VERSION ""

NS_ :

BS_:

BU_: Receiver ChassisBus VehicleBus

BO_ 962 ID3C2VCLswitches: 8 VehicleBus

BO_ 822 ID336MaxPowerRating: 3 VehicleBus
 SG_ Drive_Regen_Rating336 : 16|8@1+ (1,-100) [-100|155] "kW" Vector__XXX
 SG_ Drive_Power_Rating336 : 0|9@1+ (1,0) [0|511] "kW" Vector__XXX

BO_ 819 ID333UIcharging: 4 VehicleBus
 SG_ Charge_To_SOC333 : 16|10@1+ (0.1,0) [0|102.3] "%" Vector__XXX
 SG_ Charge_Current_Limit333 : 8|7@1+ (1,0) [0|127] "A" Vector__XXX

BO_ 577 ID241Coolant: 7 VehicleBus
 SG_ VCFPT_Coolant_Flow241 : 22|9@1+ (0.1,0) [0|51.1] "LPM" Vector__XXX
 SG_ VCF_batt_Coolant_Flow241 : 0|9@1+ (0.1,0) [0|51.1] "LPM" Vector__XXX

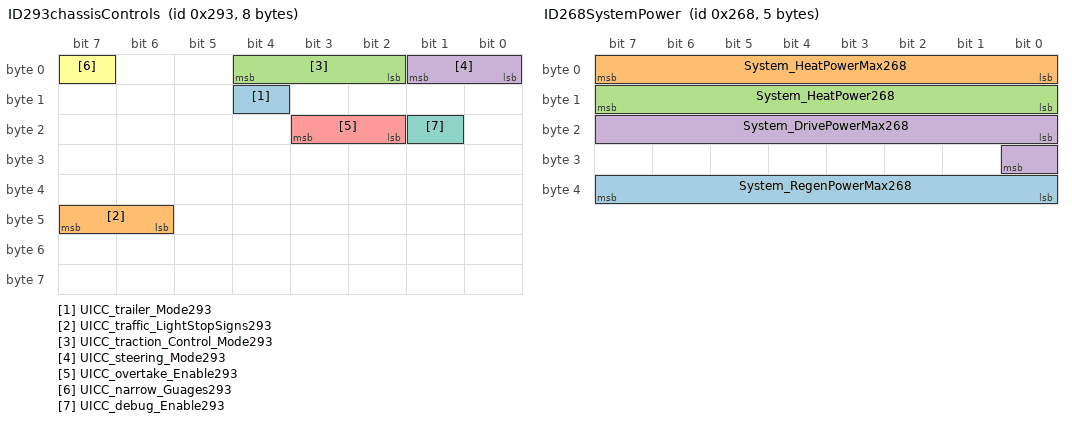
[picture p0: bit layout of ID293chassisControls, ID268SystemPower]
BO_ 659 ID293chassisControls: 8 VehicleBus
 SG_ UICC_trailer_Mode293 : 12|1@1+ (1,0) [0|1] "" Vector__XXX
 SG_ UICC_traffic_LightStopSigns293 : 46|2@1+ (1,0) [0|0] "" Vector__XXX
 SG_ UICC_traction_Control_Mode293 : 2|3@1+ (1,0) [0|7] "" Vector__XXX
 SG_ UICC_steering_Mode293 : 0|2@1+ (1,0) [0|3] "" Vector__XXX
 SG_ UICC_overtake_Enable293 : 18|2@1+ (1,0) [0|0] "" Vector__XXX
 SG_ UICC_narrow_Guages293 : 7|1@1+ (1,0) [0|1] "" Vector__XXX
 SG_ UICC_debug_Enable293 : 17|1@1+ (1,0) [0|1] "" Vector__XXX

BO_ 616 ID268SystemPower: 5 VehicleBus
 SG_ System_RegenPowerMax268 : 32|8@1+ (1,-100) [-100|155] "kW" Vector__XXX
 SG_ System_HeatPowerMax268 : 0|8@1+ (0.08,0) [0|31875] "kW" Vector__XXX
 SG_ System_HeatPower268 : 8|8@1+ (0.08,0) [0|31875] "kW" Vector__XXX
 SG_ System_DrivePowerMax268 : 16|9@1+ (1,0) [0|511] "kW" Vector__XXX

BO_ 79 ID04FGPSLatLong: 8 ChassisBus
 SG_ GPS_Longitude04F : 28|28@1- (1E-006,0) [-1342.17728|1342.17727] "Deg"  Receiver
 SG_ GPS_Lattitude04F : 0|28@1- (1E-006,0) [-134.217728|134.217727] "Deg"  Receiver

BO_ 978 ID3D2TotalChargeDischarge: 8 VehicleBus
 SG_ Total_Discharge3D2 : 0|32@1+ (0.001,0) [0|4294967.295] "kWh" Vector__XXX
 SG_ Total_Charge3D2 : 32|32@1+ (0.001,0) [0|4294967.295] "kWh" Vector__XXX

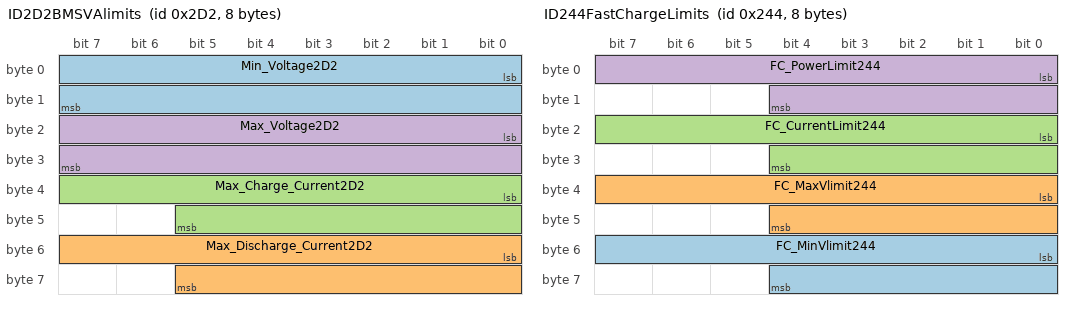
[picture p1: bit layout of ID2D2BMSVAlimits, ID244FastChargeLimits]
BO_ 722 ID2D2BMSVAlimits: 8 VehicleBus
 SG_ Min_Voltage2D2 : 0|16@1+ (0.01,0) [0|655.35] "V" Vector__XXX
 SG_ Max_Discharge_Current2D2 : 48|14@1+ (0.128,0) [0|2097.024] "A" Vector__XXX
 SG_ Max_Charge_Current2D2 : 32|14@1+ (0.1,0) [0|1638.3] "A" Vector__XXX
 SG_ Max_Voltage2D2 : 16|16@1+ (0.01,0) [0|655.35] "V" Vector__XXX

BO_ 1345 ID541FastChargeMaxLimits: 8 VehicleBus
 SG_ FCMax_Power_Limit541 : 0|13@1+ (0.062256,0) [0|509.938896] "kW" Vector__XXX
 SG_ FCMax_Current_Limit541 : 16|13@1+ (0.073242,0) [0|599.925222] "A" Vector__XXX

BO_ 580 ID244FastChargeLimits: 8 VehicleBus
 SG_ FC_MinVlimit244 : 48|13@1+ (0.073242,0) [0|599.925222] "V" Vector__XXX
 SG_ FC_MaxVlimit244 : 32|13@1+ (0.073242,0) [0|599.925222] "V" Vector__XXX
 SG_ FC_CurrentLimit244 : 16|13@1+ (0.073242,0) [0|599.925222] "A" Vector__XXX
 SG_ FC_PowerLimit244 : 0|13@1+ (0.062256,0) [0|509.938896] "kW" Vector__XXX

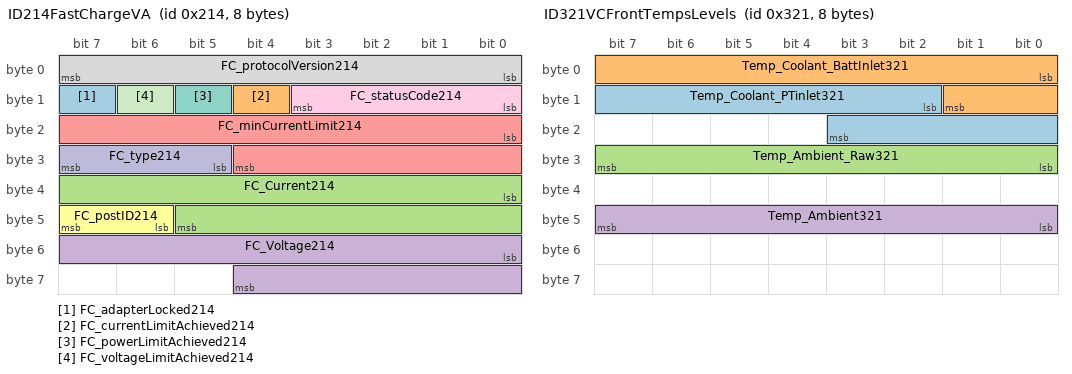
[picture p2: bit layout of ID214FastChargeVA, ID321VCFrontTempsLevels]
BO_ 532 ID214FastChargeVA: 8 VehicleBus
 SG_ FC_adapterLocked214 : 15|1@1+ (1,0) [0|0] "" Vector__XXX
 SG_ FC_currentLimitAchieved214 : 12|1@1+ (1,0) [0|0] "" Vector__XXX
 SG_ FC_Current214 : 32|14@1- (0.0732422,0) [-600.0001024|599.9268602] "A" Vector__XXX
 SG_ FC_Voltage214 : 48|13@1+ (0.0732422,0) [0|599.9268602] "V" Vector__XXX
 SG_ FC_minCurrentLimit214 : 16|13@1+ (0.1,0) [0|819.1] "A" Vector__XXX
 SG_ FC_postID214 : 46|2@1+ (2,0) [0|6] "" Vector__XXX
 SG_ FC_powerLimitAchieved214 : 13|1@1+ (1,0) [0|0] "" Vector__XXX
 SG_ FC_protocolVersion214 : 0|8@1+ (1,0) [0|255] "" Vector__XXX
 SG_ FC_statusCode214 : 8|4@1+ (1,0) [0|0] "" Vector__XXX
 SG_ FC_type214 : 29|3@1+ (1,0) [0|7] "" Vector__XXX
 SG_ FC_voltageLimitAchieved214 : 14|1@1+ (1,0) [0|0] "" Vector__XXX

BO_ 533 ID215FCisolation: 1 VehicleBus
 SG_ FCIsolation215 : 0|8@1+ (40,0) [0|10200] "kOhm" Vector__XXX

BO_ 535 ID217FCinfo: 8 VehicleBus
 SG_ FCinfoMux217 M : 0|7@1+ (1,0) [0|127] "" Vector__XXX
 SG_ FCclass217 m0 : 8|8@1+ (1,0) [0|255] "" Vector__XXX
 SG_ FCbrand217 m0 : 16|4@1+ (1,0) [0|15] "" Vector__XXX
 SG_ FCcoolingType217 m0 : 20|4@1+ (1,0) [0|15] "" Vector__XXX
 SG_ FCuiStopType217 m0 : 24|4@1+ (1,0) [0|15] "" Vector__XXX

BO_ 801 ID321VCFrontTempsLevels: 8 VehicleBus
 SG_ Temp_Coolant_PTinlet321 : 10|10@1+ (0.125,-40) [-40|87.875] "C" Vector__XXX
 SG_ Temp_Coolant_BattInlet321 : 0|10@1+ (0.125,-40) [-40|87.875] "C" Vector__XXX
 SG_ Temp_Ambient_Raw321 : 24|8@1+ (0.5,-40) [-40|87.5] "C" Vector__XXX
 SG_ Temp_Ambient321 : 40|8@1+ (0.5,-40) [-40|87.5] "C" Vector__XXX

BO_ 984 ID3D8Elevation: 2 VehicleBus
 SG_ Elevation3D8 : 0|16@1- (1,0) [-32768|32767] "M" Vector__XXX

BO_ 1320 ID528UnixTime: 4 VehicleBus
 SG_ Unix_Time528 : 0|32@0+ (1,0) [0|0] "Sec" Vector__XXX

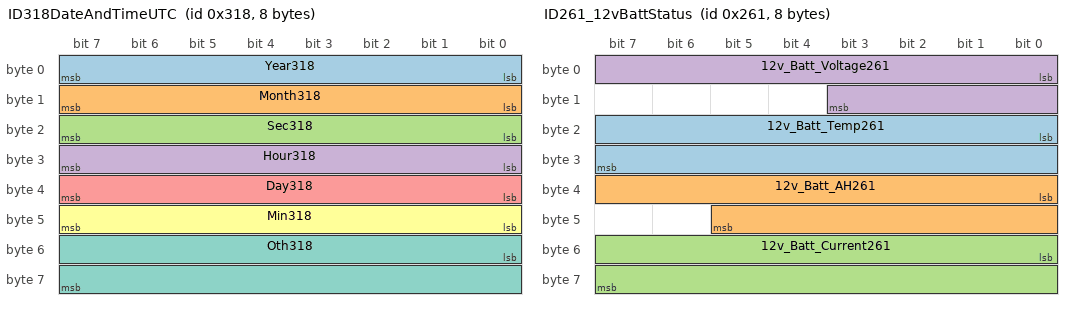
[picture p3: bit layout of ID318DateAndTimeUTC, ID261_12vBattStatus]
BO_ 792 ID318DateAndTimeUTC: 8 VehicleBus
 SG_ Year318 : 0|8@1+ (1,0) [0|0] "Yr" Vector__XXX
 SG_ Month318 : 8|8@1+ (1,0) [0|0] "Mth" Vector__XXX
 SG_ Sec318 : 16|8@1+ (1,0) [0|0] "Sec" Vector__XXX
 SG_ Hour318 : 24|8@1+ (1,0) [0|0] "Hr" Vector__XXX
 SG_ Day318 : 32|8@1+ (1,0) [0|0] "Day" Vector__XXX
 SG_ Min318 : 40|8@1+ (1,0) [0|0] "Min" Vector__XXX
 SG_ Oth318 : 48|16@1+ (1,0) [0|0] "Unk" Vector__XXX

BO_ 609 ID261_12vBattStatus: 8 VehicleBus
 SG_ 12v_Batt_Temp261 : 16|16@1- (0.01,0) [-327.68|327.67] "C" Vector__XXX
 SG_ 12v_Batt_AH261 : 32|14@1+ (0.01,0) [0|163.83] "AH" Vector__XXX
 SG_ 12v_Batt_Current261 : 48|16@1- (0.005,0) [-163.84|163.835] "A" Vector__XXX
 SG_ 12v_Batt_Voltage261 : 0|12@1+ (0.00544368,0) [0|22.2918696] "V" Vector__XXX

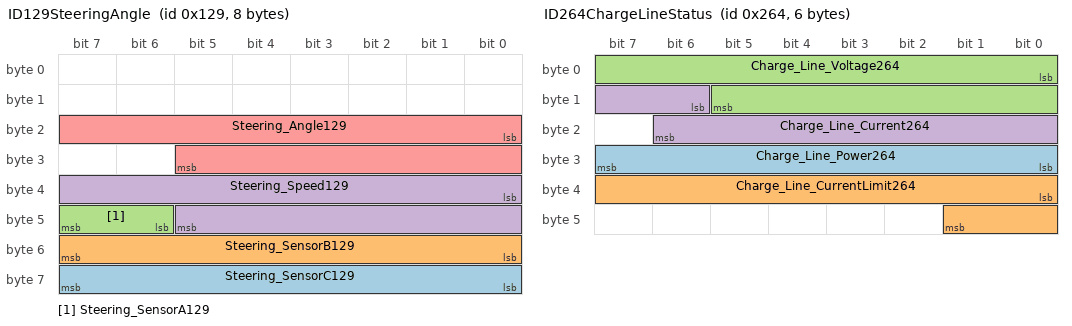
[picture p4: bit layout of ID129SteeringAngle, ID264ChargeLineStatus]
BO_ 297 ID129SteeringAngle: 8 VehicleBus
 SG_ Steering_SensorC129 : 56|8@1+ (1,0) [0|255] "" Vector__XXX
 SG_ Steering_SensorB129 : 48|8@1+ (1,0) [0|255] "" Vector__XXX
 SG_ Steering_SensorA129 : 46|2@1+ (1,0) [0|3] "" Vector__XXX
 SG_ Steering_Speed129 : 32|14@1+ (0.5,-4096) [-4096|4095.5] "D/S" Vector__XXX
 SG_ Steering_Angle129 : 16|14@1+ (0.1,-819.2) [-819.2|819.1] "Deg" Vector__XXX

BO_ 612 ID264ChargeLineStatus: 6 VehicleBus
 SG_ Charge_Line_Power264 : 24|8@1+ (0.1,0) [0|25.5] "kW" Vector__XXX
 SG_ Charge_Line_CurrentLimit264 : 32|10@1+ (0.1,0) [0|102.3] "A" Vector__XXX
 SG_ Charge_Line_Voltage264 : 0|14@1+ (0.0333,0) [0|545.5539] "V" Vector__XXX
 SG_ Charge_Line_Current264 : 14|9@1+ (0.1,0) [0|51.1] "A" Vector__XXX

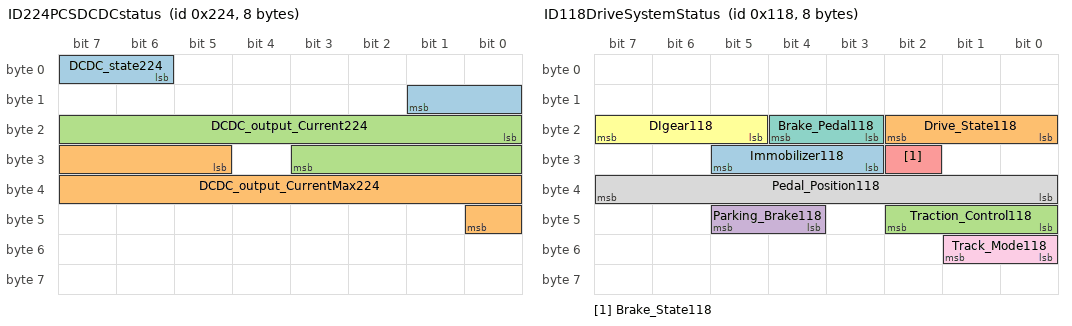
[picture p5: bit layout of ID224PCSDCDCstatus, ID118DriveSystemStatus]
BO_ 548 ID224PCSDCDCstatus: 8 VehicleBus
 SG_ DCDC_state224 : 6|4@1+ (1,0) [0|15] "" Vector__XXX
 SG_ DCDC_output_CurrentMax224 : 29|12@1+ (0.1,0) [0|409.5] "A" Vector__XXX
 SG_ DCDC_output_Current224 : 16|12@1- (0.1,0) [-204.8|204.7] "A" Vector__XXX

BO_ 280 ID118DriveSystemStatus: 8 VehicleBus
 SG_ Immobilizer118 : 27|3@1+ (1,0) [0|0] "" Vector__XXX
 SG_ Drive_State118 : 16|3@1+ (1,0) [0|7] "" Vector__XXX
 SG_ Traction_Control118 : 40|3@1+ (1,0) [0|7] "" Vector__XXX
 SG_ Parking_Brake118 : 44|2@1+ (1,0) [0|15] "" Vector__XXX
 SG_ Brake_State118 : 26|1@1+ (1,0) [0|1] "" Vector__XXX
 SG_ DIgear118 : 21|3@1+ (1,0) [0|7] "" Vector__XXX
 SG_ Brake_Pedal118 : 19|2@1+ (1,0) [0|3] "" Vector__XXX
 SG_ Pedal_Position118 : 32|8@1+ (0.4,0) [0|102] "%" Vector__XXX
 SG_ Track_Mode118 : 48|2@1+ (1,0) [0|255] "" Vector__XXX

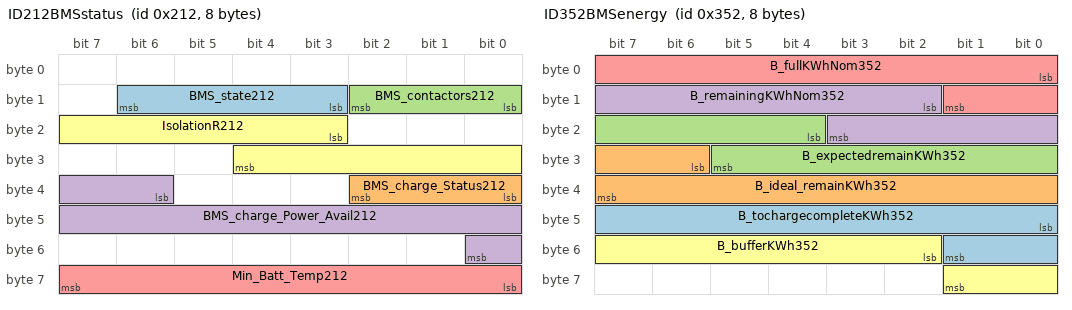
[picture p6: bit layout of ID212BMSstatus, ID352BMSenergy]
BO_ 530 ID212BMSstatus: 8 VehicleBus
 SG_ BMS_state212 : 11|4@1+ (1,0) [0|15] "" Vector__XXX
 SG_ BMS_charge_Status212 : 32|3@1+ (1,0) [0|7] "" Vector__XXX
 SG_ BMS_contactors212 : 8|3@1+ (1,0) [0|7] "" Vector__XXX
 SG_ BMS_charge_Power_Avail212 : 38|11@1+ (0.125,0) [0|255.875] "kW" Vector__XXX
 SG_ Min_Batt_Temp212 : 56|8@1+ (0.5,-40) [-40|87.5] "C" Vector__XXX
 SG_ IsolationR212 : 19|10@1+ (1,0) [0|1023] "kOhm" Vector__XXX

BO_ 850 ID352BMSenergy: 8 VehicleBus
 SG_ B_tochargecompleteKWh352 : 40|10@1+ (0.1,0) [0|102.3] "kWh" Vector__XXX
 SG_ B_ideal_remainKWh352 : 30|10@1+ (0.1,0) [0|102.3] "kWh" Vector__XXX
 SG_ B_expectedremainKWh352 : 20|10@1+ (0.1,0) [0|102.3] "kWh" Vector__XXX
 SG_ B_remainingKWhNom352 : 10|10@1+ (0.1,0) [0|102.3] "kWh" Vector__XXX
 SG_ B_fullKWhNom352 : 0|10@1+ (0.1,0) [0|102.3] "kWh" Vector__XXX
 SG_ B_bufferKWh352 : 50|8@1+ (0.1,0) [0|25.5] "kWh" Vector__XXX

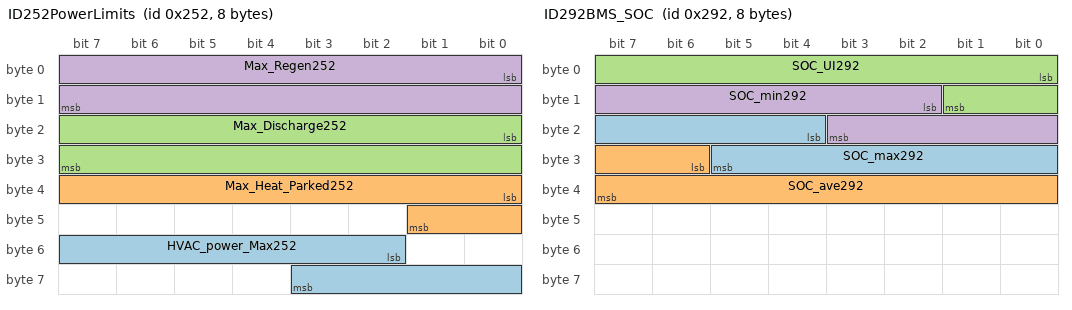
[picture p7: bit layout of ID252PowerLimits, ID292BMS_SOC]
BO_ 594 ID252PowerLimits: 8 VehicleBus
 SG_ HVAC_power_Max252 : 50|10@1+ (0.02,0) [0|20.46] "kW" Vector__XXX
 SG_ Max_Heat_Parked252 : 32|10@1+ (0.1,0) [0|102.3] "kW" Vector__XXX
 SG_ Max_Discharge252 : 16|16@1+ (0.01,0) [0|655.35] "kW" Vector__XXX
 SG_ Max_Regen252 : 0|16@1+ (0.01,0) [0|655.35] "kW" Vector__XXX

BO_ 786 ID312BMSthermal: 8 VehicleBus
 SG_ BMSdissipation312 : 0|10@1+ (0.02,0) [0|20.46] "kW" Vector__XXX

BO_ 658 ID292BMS_SOC: 8 VehicleBus
 SG_ SOC_max292 : 20|10@1+ (0.1,0) [0|102.3] "" Vector__XXX
 SG_ SOC_ave292 : 30|10@1+ (0.1,0) [0|102.3] "" Vector__XXX
 SG_ SOC_UI292 : 0|10@1+ (0.1,0) [0|102.3] "" Vector__XXX
 SG_ SOC_min292 : 10|10@1+ (0.1,0) [0|102.3] "" Vector__XXX

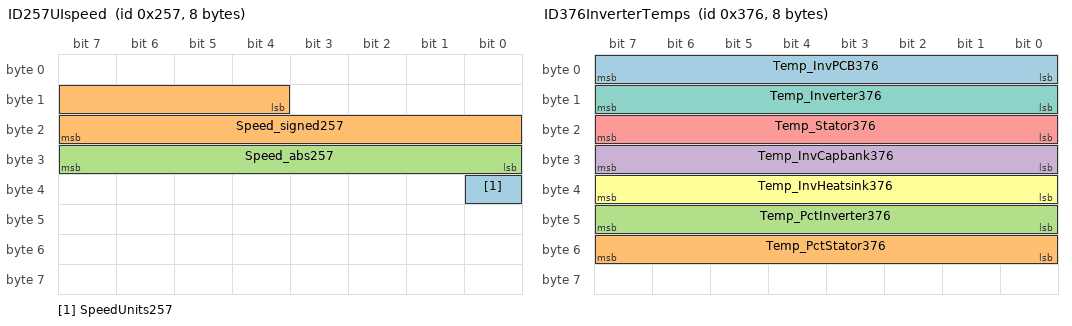
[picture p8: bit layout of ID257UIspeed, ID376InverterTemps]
BO_ 599 ID257UIspeed: 8 VehicleBus
 SG_ SpeedUnits257 : 32|1@1+ (1,0) [0|0] "" Vector__XXX
 SG_ Speed_signed257 : 12|12@1+ (0.05,-25) [-25|179.75] "MPH" Vector__XXX
 SG_ Speed_abs257 : 24|8@1+ (1,0) [0|255] "MPH" Vector__XXX

BO_ 1029 ID405VIN: 8 VehicleBus
 SG_ VINB405 m17 : 8|56@1+ (1,0) [0|7.2057594038E+016] "" Vector__XXX
 SG_ VINC405 m18 : 8|56@1+ (1,0) [0|7.2057594038E+016] "" Vector__XXX
 SG_ VINA405 m16 : 8|56@1+ (1,0) [0|7.2057594038E+016] "" Vector__XXX
 SG_ mux405 M : 0|8@1+ (1,0) [0|255] "" Vector__XXX

BO_ 886 ID376InverterTemps: 8 VehicleBus
 SG_ Temp_InvPCB376 : 0|8@1+ (1,-40) [-40|215] "C" Vector__XXX
 SG_ Temp_PctStator376 : 48|8@1+ (0.4,0) [0|102] "%" Vector__XXX
 SG_ Temp_PctInverter376 : 40|8@1+ (0.4,0) [0|102] "%" Vector__XXX
 SG_ Temp_InvCapbank376 : 24|8@1+ (1,-40) [-40|215] "C" Vector__XXX
 SG_ Temp_Stator376 : 16|8@1+ (1,-40) [-40|215] "C" Vector__XXX
 SG_ Temp_InvHeatsink376 : 32|8@1+ (1,-40) [-40|215] "C" Vector__XXX
 SG_ Temp_Inverter376 : 8|8@1+ (1,-40) [-40|215] "C" Vector__XXX

BO_ 340 ID154: 8 VehicleBus
 SG_ RAW_Torque154 : 40|12@1- (0.25,0) [-512|511.75] "NM" Vector__XXX

BO_ 950 ID3B6odometer: 4 VehicleBus
 SG_ Odometer3B6 : 0|32@1+ (0.001,0) [0|4294967.295] "KM" Vector__XXX

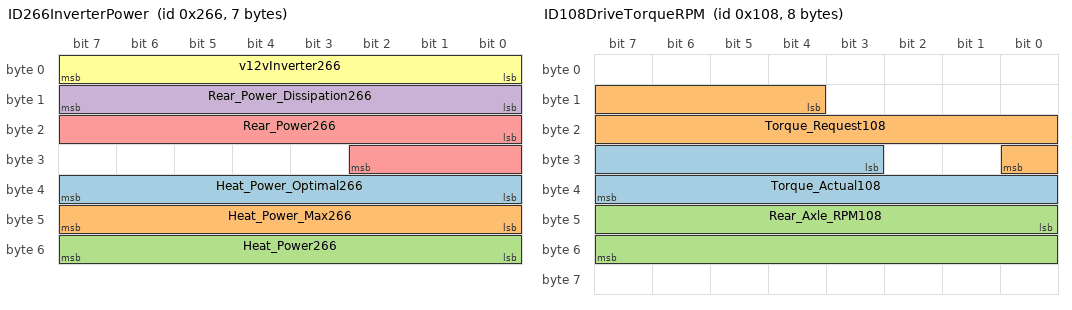
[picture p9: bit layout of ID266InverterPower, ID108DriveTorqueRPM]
BO_ 614 ID266InverterPower: 7 VehicleBus
 SG_ Heat_Power_Optimal266 : 32|8@1+ (0.08,0) [0|31875] "kW" Vector__XXX
 SG_ Heat_Power_Max266 : 40|8@1+ (0.08,0) [0|31875] "kW" Vector__XXX
 SG_ Heat_Power266 : 48|8@1+ (0.08,0) [0|31875] "kW" Vector__XXX
 SG_ Rear_Power_Dissipation266 : 8|8@1+ (0.125,-0.5) [-0.5|31.375] "kW" Vector__XXX
 SG_ Rear_Power266 : 16|11@1- (0.5,0) [-512|511.5] "kW" Vector__XXX
 SG_ v12vInverter266 : 0|8@1+ (0.1,0) [0|25.5] "Volts" Vector__XXX

BO_ 264 ID108DriveTorqueRPM: 8 VehicleBus
 SG_ Torque_Actual108 : 27|13@1- (0.2,0) [-819.2|819] "NM"  Receiver
 SG_ Torque_Request108 : 12|13@1- (0.2,0) [-819.2|819] "NM"  Receiver
 SG_ Rear_Axle_RPM108 : 40|16@1- (0.1,0) [-3276.8|3276.7] "RPM"  Receiver

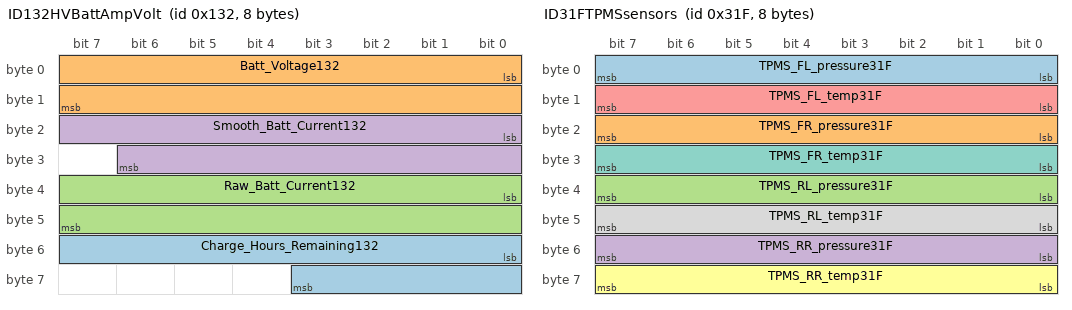
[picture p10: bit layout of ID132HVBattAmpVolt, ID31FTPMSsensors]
BO_ 306 ID132HVBattAmpVolt: 8 VehicleBus
 SG_ Charge_Hours_Remaining132 : 48|12@1+ (1,0) [0|4095] "Min" Vector__XXX
 SG_ Batt_Voltage132 : 0|16@1+ (0.01,0) [0|655.35] "V" Vector__XXX
 SG_ Raw_Batt_Current132 : 32|16@1+ (-0.05,1000) [-2276.75|1000] "A" Vector__XXX
 SG_ Smooth_Batt_Current132 : 16|15@1+ (-0.1,1000) [-2276.7|1000] "A" Vector__XXX

BO_ 294 ID126: 8 VehicleBus
 SG_ Demand126 : 16|16@1+ (1,0) [0|65535] "" Vector__XXX
 SG_ Batt_Voltage126 : 0|16@1+ (0.5,0) [0|32767.5] "Volts" Vector__XXX

BO_ 799 ID31FTPMSsensors: 8 ChassisBus
 SG_ TPMS_FL_pressure31F : 0|8@1+ (0.025,0) [0|0] "bar" Vector__XXX
 SG_ TPMS_FR_pressure31F : 16|8@1+ (0.025,0) [0|0] "bar" Vector__XXX
 SG_ TPMS_RL_pressure31F : 32|8@1+ (0.025,0) [0|0] "bar" Vector__XXX
 SG_ TPMS_RR_pressure31F : 48|8@1+ (0.025,0) [0|0] "bar" Vector__XXX
 SG_ TPMS_FL_temp31F : 8|8@1+ (1,-40) [0|0] "degC" Vector__XXX
 SG_ TPMS_RR_temp31F : 56|8@1+ (1,-40) [0|0] "degC" Vector__XXX
 SG_ TPMS_FR_temp31F : 24|8@1+ (1,-40) [0|0] "degC" Vector__XXX
 SG_ TPMS_RL_temp31F : 40|8@1+ (1,-40) [0|0] "degC" Vector__XXX

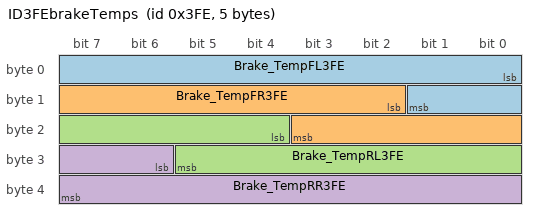
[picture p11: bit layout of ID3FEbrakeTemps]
BO_ 1022 ID3FEbrakeTemps: 5 VehicleBus
 SG_ Brake_TempFL3FE : 0|10@1+ (1,-40) [0|0] "C" Vector__XXX
 SG_ Brake_TempFR3FE : 10|10@1+ (1,-40) [0|0] "C" Vector__XXX
 SG_ Brake_TempRL3FE : 20|10@1+ (1,-40) [0|0] "C" Vector__XXX
 SG_ Brake_TempRR3FE : 30|10@1+ (1,-40) [0|0] "C" Vector__XXX

BO_ 2047 ID7FFcarConfig: 8 VehicleBus
 SG_ CFG_muxindex7FF M : 0|8@1+ (1,0) [0|0] "" Vector__XXX
 SG_ CFG_airSuspension7FF m1 : 8|1@1+ (1,0) [0|0] "" Vector__XXX
 SG_ CFG_epasType7FF m1 : 9|1@1+ (1,0) [0|0] "" Vector__XXX
 SG_ CFG_drivetrainType7FF m1 : 10|1@1+ (1,0) [0|0] "" Vector__XXX
 SG_ CFG_rightHandDrive7FF m1 : 11|1@1+ (1,0) [0|0] "" Vector__XXX
 SG_ CFG_country7FF m1 : 16|16@1+ (1,0) [0|0] "" Vector__XXX
 SG_ CFG_heatedWipers7FF m2 : 8|1@1+ (1,0) [0|0] "" Vector__XXX
 SG_ CFG_frontSeatHeaters7FF m2 : 9|1@1+ (1,0) [0|0] "" Vector__XXX
 SG_ CFG_rearSeatHeaters7FF m2 : 10|1@1+ (1,0) [0|0] "" Vector__XXX
 SG_ CFG_packEnergy7FF m2 : 11|1@1+ (1,0) [0|0] "" Vector__XXX
 SG_ CFG_brakeHWType7FF m2 : 12|1@1+ (1,0) [0|0] "" Vector__XXX
 SG_ CFG_homelinkType7FF m2 : 13|1@1+ (1,0) [0|0] "" Vector__XXX
 SG_ CFG_vdcType7FF m2 : 14|1@1+ (1,0) [0|0] "" Vector__XXX
 SG_ CFG_xcpIbst7FF m2 : 15|1@1+ (1,0) [0|0] "" Vector__XXX
 SG_ CFG_xcpESP7FF m2 : 16|1@1+ (1,0) [0|0] "" Vector__XXX
 SG_ CFG_memoryMirrors7FF m2 : 17|1@1+ (1,0) [0|0] "" Vector__XXX
 SG_ CFG_powerSteeringColumn7FF m2 : 18|1@1+ (1,0) [0|0] "" Vector__XXX
 SG_ CFG_interiorLighting7FF m2 : 19|1@1+ (1,0) [0|0] "" Vector__XXX
 SG_ CFG_frontFogLamps7FF m2 : 20|1@1+ (1,0) [0|0] "" Vector__XXX
 SG_ CFG_headlamps7FF m2 : 21|1@1+ (1,0) [0|0] "" Vector__XXX
 SG_ CFG_audioType7FF m2 : 22|1@1+ (1,0) [0|0] "" Vector__XXX
 SG_ CFG_lumbarECUType7FF m2 : 23|1@1+ (1,0) [0|0] "" Vector__XXX
 SG_ CFG_ibstWakeType7FF m2 : 24|1@1+ (1,0) [0|0] "" Vector__XXX
 SG_ CFG_frontSeatType7FF m2 : 25|1@1+ (1,0) [0|1] "" Vector__XXX
 SG_ CFG_auxParkLamps7FF m2 : 26|1@1+ (1,0) [0|0] "" Vector__XXX
 SG_ CFG_pedestrianWarningSound7FF m2 : 27|1@1+ (1,0) [0|0] "" Vector__XXX
 SG_ CFG_hvacQuietSnorkelType7FF m2 : 28|1@1+ (1,0) [0|0] "" Vector__XXX
 SG_ CFG_hvacPanelVaneType7FF m2 : 29|1@1+ (1,0) [0|0] "" Vector__XXX
 SG_ CFG_CabinBlowerCtrlType7FF m2 : 30|1@1+ (1,0) [0|0] "" Vector__XXX
 SG_ CFG_performancePackage7FF m2 : 31|1@1+ (1,0) [0|0] "" Vector__XXX
 SG_ CFG_eBuckConfig7FF m2 : 32|1@1+ (1,0) [0|0] "" Vector__XXX
 SG_ CFG_windshieldType7FF m2 : 33|1@1+ (1,0) [0|0] "" Vector__XXX
 SG_ CFG_activeHighBeam7FF m2 : 34|1@1+ (1,0) [0|0] "" Vector__XXX
 SG_ CFG_airbagCutoffSwitch7FF m2 : 35|1@1+ (1,0) [0|0] "" Vector__XXX
 SG_ CFG_intrusionSensorType7FF m2 : 36|1@1+ (1,0) [0|0] "" Vector__XXX
 SG_ CFG_spoilerType7FF m2 : 37|1@1+ (1,0) [0|0] "" Vector__XXX
 SG_ CFG_rearGlassType7FF m2 : 38|1@1+ (1,0) [0|0] "" Vector__XXX
 SG_ CFG_rearFogLamps7FF m2 : 39|1@1+ (1,0) [0|0] "" Vector__XXX
 SG_ CFG_roofType7FF m2 : 40|2@1+ (1,0) [0|3] "" Vector__XXX
 SG_ CFG_autopilot7FF m2 : 42|2@1+ (1,0) [0|3] "" Vector__XXX
 SG_ CFG_superchargingAccess7FF m2 : 44|2@1+ (1,0) [0|3] "" Vector__XXX
 SG_ CFG_wheelType7FF m2 : 46|2@1+ (1,0) [0|3] "" Vector__XXX
 SG_ CFG_exteriorColor7FF m2 : 48|3@1+ (1,0) [0|7] "" Vector__XXX
 SG_ CFG_numberHVILNodes7FF m2 : 51|3@1+ (1,1) [1|8] "" Vector__XXX
 SG_ CFG_restraintsHardwareType7FF m2 : 56|5@1+ (1,0) [0|31] "" Vector__XXX
 SG_ CFG_m3Raw7FF m3 : 8|56@1+ (1,0) [0|0] "" Vector__XXX

EV_ MtoK: 0 [0|0] "" 0 1 DUMMY_NODE_VECTOR0 Vector__XXX;

EV_ MPH: 0 [0|0] "MPH" 0 2 DUMMY_NODE_VECTOR0 Vector__XXX;

EV_ Milage: 0 [0|0] "Mi" 0 3 DUMMY_NODE_VECTOR0 Vector__XXX;

EV_ Torque154: 0 [0|0] "NM" 0 4 DUMMY_NODE_VECTOR0 Vector__XXX;

CM_ SG_ 722 MinVoltage2D2 "test";
CM_ SG_ 612 ChargeLinePower264 "16 8 .08";
CM_ SG_ 612 ChargeLineCurrentLimit264 "32 8 .5";
CM_ SG_ 612 ChargeLineVoltage264 "0 12 .1";
CM_ SG_ 612 ChargeLineCurrent264 "24 8 .5";
CM_ SG_ 280 DIgear118 "20 4";
CM_ SG_ 280 BrakePedal118 "19 1";
CM_ SG_ 594 MaxHeatParked252 "test";
CM_ SG_ 599 UIspeedUnits257 "0-mph 1-kph";
CM_ SG_ 599 UIspeed_signed257 ".05 -25 x.08 -40 for kph";
CM_ SG_ 1029 VINB405 "last 7 of VIN (ASCII)";
CM_ SG_ 1029 VINC405 "part two of VIN (ASCII)";
CM_ SG_ 1029 VINA405 "four zeros then first 3 characters of VIN";
CM_ SG_ 886 TempInvPCB376 ".5 -20";
CM_ SG_ 886 TempInvCapbank376 ".5 -20";
CM_ SG_ 614 RearPowerDissipation266 "should offset be there?";
CM_ SG_ 264 TorqueActual108 "sb24 16 .026";
CM_ SG_ 264 TorqueRequest108 "scale?";
BA_DEF_ BO_  "GenMsgSendType" ENUM  "Cyclic","SendType1","SendType2","SendType3","SendType4","SendType5","SendType6","SendType7","SendType8","SendType9";
BA_DEF_ BO_  "GenMsgCycleTime" INT 0 0;
BA_DEF_  "BusType" STRING ;
BA_DEF_ BO_  "GenMsgAutoGenSnd" ENUM  "No","Yes";
BA_DEF_ BO_  "GenMsgAutoGenDsp" ENUM  "No","Yes";
BA_DEF_ SG_  "GenSigEnvVarType" ENUM  "int","float","undef";
BA_DEF_ BU_  "GenNodAutoGenSnd" ENUM  "No","Yes";
BA_DEF_ BU_  "GenNodAutoGenDsp" ENUM  "No","Yes";
BA_DEF_  "GenEnvVarEndingDsp" STRING ;
BA_DEF_  "GenEnvVarEndingSnd" STRING ;
BA_DEF_  "GenEnvVarPrefix" STRING ;
BA_DEF_  "Modified" STRING ;
BA_DEF_DEF_  "GenMsgSendType" "Cyclic";
BA_DEF_DEF_  "GenMsgCycleTime" 0;
BA_DEF_DEF_  "BusType" "";
BA_DEF_DEF_  "GenMsgAutoGenSnd" "Yes";
BA_DEF_DEF_  "GenMsgAutoGenDsp" "Yes";
BA_DEF_DEF_  "GenSigEnvVarType" "undef";
BA_DEF_DEF_  "GenNodAutoGenSnd" "Yes";
BA_DEF_DEF_  "GenNodAutoGenDsp" "Yes";
BA_DEF_DEF_  "GenEnvVarEndingDsp" "Dsp";
BA_DEF_DEF_  "GenEnvVarEndingSnd" "Snd";
BA_DEF_DEF_  "GenEnvVarPrefix" "Env";
BA_DEF_DEF_  "Modified" "JW2019Feb20";
BA_ "BusType" "CAN";
BA_ "GenMsgCycleTime" BO_ 962 50;
BA_ "GenMsgCycleTime" BO_ 822 1000;
BA_ "GenMsgCycleTime" BO_ 819 500;
BA_ "GenMsgCycleTime" BO_ 577 100;
BA_ "GenMsgCycleTime" BO_ 659 500;
BA_ "GenMsgCycleTime" BO_ 616 100;
BA_ "GenMsgCycleTime" BO_ 79 1000;
BA_ "GenMsgCycleTime" BO_ 978 1000;
BA_ "GenMsgCycleTime" BO_ 722 100;
BA_ "GenMsgCycleTime" BO_ 1345 100;
BA_ "GenMsgCycleTime" BO_ 580 100;
BA_ "GenMsgCycleTime" BO_ 532 100;
BA_ "GenMsgCycleTime" BO_ 533 1000;
BA_ "GenMsgCycleTime" BO_ 535 1000;
BA_ "GenMsgCycleTime" BO_ 801 1000;
BA_ "GenMsgCycleTime" BO_ 984 1000;
BA_ "GenMsgCycleTime" BO_ 609 100;
BA_ "GenMsgCycleTime" BO_ 297 10;
BA_ "GenMsgCycleTime" BO_ 612 100;
BA_ "GenMsgCycleTime" BO_ 548 100;
BA_ "GenMsgCycleTime" BO_ 280 10;
BA_ "GenMsgCycleTime" BO_ 530 100;
BA_ "GenMsgCycleTime" BO_ 850 1000;
BA_ "GenMsgCycleTime" BO_ 594 100;
BA_ "GenMsgCycleTime" BO_ 786 1000;
BA_ "GenMsgCycleTime" BO_ 658 100;
BA_ "GenMsgCycleTime" BO_ 599 20;
BA_ "GenMsgCycleTime" BO_ 1029 205;
BA_ "GenMsgCycleTime" BO_ 886 1000;
BA_ "GenMsgCycleTime" BO_ 340 10;
BA_ "GenMsgCycleTime" BO_ 950 1000;
BA_ "GenMsgCycleTime" BO_ 614 10;
BA_ "GenMsgCycleTime" BO_ 264 10;
BA_ "GenMsgCycleTime" BO_ 306 10;
BA_ "GenMsgCycleTime" BO_ 294 100;
BA_ "GenMsgCycleTime" BO_ 799 1000;
BA_ "GenMsgCycleTime" BO_ 1022 1000;
BA_ "GenMsgCycleTime" BO_ 2047 100;
VAL_ 659 UICCtractionControlMode293 1 "SlipStart" 0 "FullTraction" ;
VAL_ 659 UICCsteeringMode293 2 "Sport" 1 "Standard" 0 "Comfort" ;
VAL_ 532 FCtype214 7 "error" 6 "other" 5 "MCEVSE" 4 "Combo" 3 "CCS" 2 "GB" 1 "CHADEMO" 0 "Supercharger" ;
VAL_ 535 FCclass217 2 "UrbanSC" 1 "Supercharger" 0 "err" ;
VAL_ 535 FCbrand217 1 "Tesla" 0 "err" ;
VAL_ 535 FCcoolingType217 2 "Liquid" 1 "Convection" 0 "err" ;
VAL_ 548 DCDCstate224 6 "Error" 5 "Shutdown" 4 "HVactive" 3 "Precharge" 2 "PrechargeStart" 1 "12vChg" 0 "Idle" ;
VAL_ 280 DriveState118 5 "Driving" 2 "Park" 1 "Charging" 0 "Idle" ;
VAL_ 280 TractionControl118 1 "SlipStart" 0 "Standard" ;
VAL_ 280 ParkingBrake118 2 "Disengage" 1 "Engage" 0 "Idle" ;
VAL_ 280 BrakeState118 1 "Hold" ;
VAL_ 280 DIgear118 3 "Neutral" 7 "Idle" 1 "Park" 2 "Reverse" 4 "Drive" ;
VAL_ 280 BrakePedal118 1 "Brake" ;
VAL_ 530 BMSstate212 3 "Charge" 1 "Drive" 0 "Idle" ;
VAL_ 530 BMSchargeStatus212 1 "Connected" 0 "Disconnected" ;
VAL_ 530 BMScontactors212 6 "err" 5 "err" 4 "Closed" 3 "Closing" 2 "Opening" 1 "Open" 0 "err" ;
VAL_ 599 UIspeedUnits257 1 "KPH" 0 "MPH" ;
VAL_ 2047 CFGdrivetrainType7FF 1 "AWD" 0 "RWD" ;
VAL_ 2047 CFGpackEnergy7FF 1 "74kWh" 0 "50kWh" ;
VAL_ 2047 CFGinteriorLighting7FF 1 "Premium" 0 "Base" ;
VAL_ 2047 CFGheadlamps7FF 1 "Premium" 0 "Base" ;
VAL_ 2047 CFGaudioType7FF 1 "Premium" 0 "Base" ;
VAL_ 2047 CFGfrontSeatType7FF 1 "Premium" 0 "Base" ;
VAL_ 2047 CFGroofType7FF 2 "Panoramic Sunroof" 1 "Fixed Glass" 0 "Metal" ;
VAL_ 2047 CFGautopilot7FF 3 "Full Self Driving" 2 "Enhanced" 1 "Highway" 0 "None" ;
VAL_ 2047 CFGsuperchargingAccess7FF 2 "Pay as you go" 1 "Free" 0 "None" ;
VAL_ 2047 CFGwheelType7FF 2 "20" 1 "19" 0 "18" ;
VAL_ 2047 CFGexteriorColor7FF 6 "Pearl White" 5 "Deep Blue" 4 "4" 3 "Midnight Silver" 2 "Silver Metallic" 1 "Black" 0 "Red Multicoat" ;
